# SPINLOCK0_SPINLOCK0 register map
Vendor: Texas Instruments
Peripheral module from a debugger description file (folder AM263).
Registers are 32-bit, read-only, reset 0x0 unless marked. A register's access mark holds for its fields unless they carry their own. Offsets are as the file gives them; lines under a group give offsets from that group; [hi:lo] are bit positions; {n}, {i} and the like mark numbered series; 'fields as' and 'values as' point back to an identical list; <NAME> marks a mode.

## SPINLOCK0_SPINLOCK0
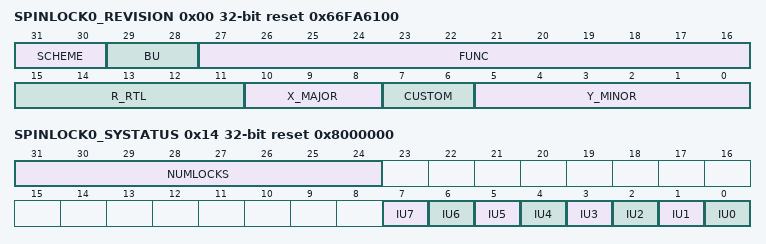
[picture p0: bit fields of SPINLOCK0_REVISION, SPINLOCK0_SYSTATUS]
0x00 SPINLOCK0_REVISION reset 0x66FA6100
  [31:30] SCHEME — Used to distinguish which ID numbering scheme is used.
  [29:28] BU — BU identifier
  [27:16] FUNC — Module family.
  [15:11] R_RTL — RTL version. R of X.Y.R.Z
  [10:8] X_MAJOR — Major revision. X of X.Y.R.Z
  [7:6] CUSTOM — Special version number
  [5:0] Y_MINOR — Minor revision. Y of X.Y.R.Z
0x10 SPINLOCK0_SYSCONFIG 8-bit rw
  [1] SOFTRESET — Module Software ResetThe bit is automatically reset by the hardware. During reads, it always returns 0It has the same effect as the hardware resetWriting a 0 has no effect. Writing a 1 will start a soft reset sequence and free all of the locks
0x14 SPINLOCK0_SYSTATUS reset 0x8000000
  [31:24] NUMLOCKS — Module configuration parameter n, the total number of spinlocks divided by 32.e.g. For 256 spin locks, this will return the number 0x08
  [n] IU{n} (n=0..7) — In-Use flag {n} covering lock registers {32n} - {32n+31}.If no lock registers are implemented in this range, then this flag always reads as 0Read 0 : All lock registers {32n} - {32n+31} are in the Not Taken stateRead 1 : At least one of the lock registers {32n} - {32n+31} are in the Taken state
0x800 SPINLOCK0_LOCK_REG size not given rw
  [0] TAKEN — Lock StatusRead 0 : Lock was previously free. The reader now has been granted the lock.Read 1 : Lock was previously taken. The reader has not been granted the lock and must retry.Write 0 : Free the lock by setting TAKEN to zero.Write 1 : No effect
